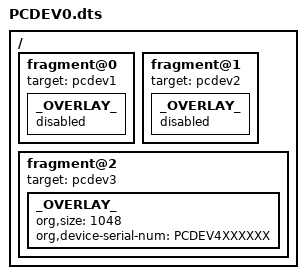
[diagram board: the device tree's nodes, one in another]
/dts-v1/;
/plugin/;

/{
	fragment@0 {
		target = <&pcdev1>;
		_OVERLAY_ {
			status = "disabled";
		};
	

	};

	fragment@1 {
		target = <&pcdev2>;
		_OVERLAY_ {
			status = "disabled";
		};
	

	};

	fragment@2 {
		target = <&pcdev3>;
		_OVERLAY_ {
			org,size = <1048>;
                	org,device-serial-num = "PCDEV4XXXXXX";

		};
	

	};



};
